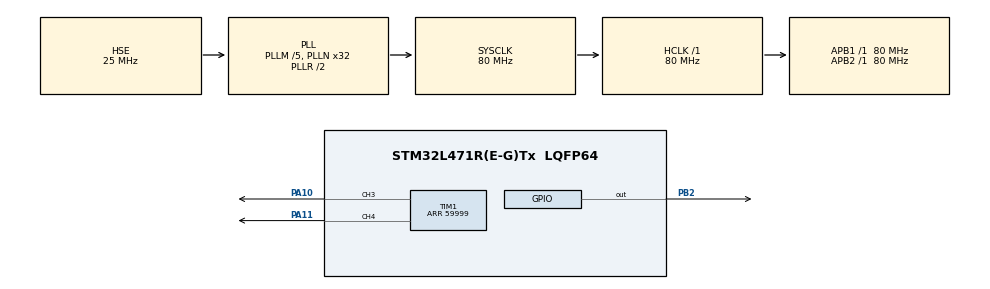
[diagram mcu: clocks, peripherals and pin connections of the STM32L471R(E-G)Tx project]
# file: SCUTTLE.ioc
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Mcu.Family=STM32L4
Mcu.Name=STM32L471R(E-G)Tx
Mcu.Package=LQFP64
NVIC.PriorityGroup=NVIC_PRIORITYGROUP_4
PA10.Signal=S_TIM1_CH3
PA11.Signal=S_TIM1_CH4
PA13\ (JTMS-SWDIO).Mode=Serial_Wire
PA13\ (JTMS-SWDIO).Signal=SYS_JTMS-SWDIO
PA14\ (JTCK-SWCLK).Mode=Serial_Wire
PA14\ (JTCK-SWCLK).Signal=SYS_JTCK-SWCLK
PB2.Signal=GPIO_Output
PB3\ (JTDO-TRACESWO).Signal=SYS_JTDO-SWO
PH0-OSC_IN\ (PH0).Mode=HSE-External-Oscillator
PH0-OSC_IN\ (PH0).Signal=RCC_OSC_IN
PH1-OSC_OUT\ (PH1).Mode=HSE-External-Oscillator
PH1-OSC_OUT\ (PH1).Signal=RCC_OSC_OUT
ProjectManager.HeapSize=0x200
ProjectManager.StackSize=0x400
ProjectManager.TargetToolchain=STM32CubeIDE
RCC.ADCFreq_Value=20000000
RCC.AHBFreq_Value=80000000
RCC.APB1Freq_Value=80000000
RCC.APB1TimFreq_Value=80000000
RCC.APB2Freq_Value=80000000
RCC.APB2TimFreq_Value=80000000
RCC.CortexFreq_Value=80000000
RCC.HCLKFreq_Value=80000000
RCC.HSE_VALUE=25000000
RCC.HSI_VALUE=16000000
RCC.LSE_VALUE=32768
RCC.MSI_VALUE=4000000
RCC.PLLM=5
RCC.PLLN=32
RCC.PLLSourceVirtual=RCC_PLLSOURCE_HSE
RCC.SYSCLKFreq_VALUE=80000000
RCC.SYSCLKSource=RCC_SYSCLKSOURCE_PLLCLK
RCC.VCOOutputFreq_Value=160000000
SH.S_TIM1_CH3.0=TIM1_CH3,PWM Generation3 CH3
SH.S_TIM1_CH4.0=TIM1_CH4,PWM Generation4 CH4
TIM1.Channel-PWM\ Generation3\ CH3=TIM_CHANNEL_3
TIM1.Channel-PWM\ Generation4\ CH4=TIM_CHANNEL_4
TIM1.Period=59999
TIM1.Pulse-PWM\ Generation4\ CH4=29999
board=custom

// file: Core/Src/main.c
/* USER CODE BEGIN Header */
/* USER CODE END Header */
#include "main.h"
#include "motor.h"

TIM_HandleTypeDef htim1;

void SystemClock_Config(void);
static void MX_GPIO_Init(void);
static void MX_TIM1_Init(void);

int main(void)
{

  /* MCU Configuration--------------------------------------------------------*/

  /* Reset of all peripherals, Initializes the Flash interface and the Systick. */
  HAL_Init();

  /* Configure the system clock */
  SystemClock_Config();

  /* Initialize all configured peripherals */
  MX_GPIO_Init();
  MX_TIM1_Init();
  /* USER CODE BEGIN 2 */

  // Start Timer 1 channels 3 and 4
  int32_t duty = -50;
  HAL_GPIO_WritePin(GPIOB, GPIO_PIN_2, GPIO_PIN_SET);
  HAL_TIM_PWM_Start(&htim1, TIM_CHANNEL_3);
  HAL_TIM_PWM_Start(&htim1, TIM_CHANNEL_4);

  // Setup motor2 with TIM1 Channel 3 and 4
  volatile uint32_t *pCCR3 = &(htim1.Instance->CCR3);
  volatile uint32_t *pCCR4 = &(htim1.Instance->CCR4);
  uint32_t Tim2Period = (htim1.Instance->ARR);
  motor_t motor2 = {pCCR3, pCCR4, Tim2Period, duty};

  /* USER CODE END 2 */

  /* Infinite loop */

  /* USER CODE BEGIN WHILE */
  while (1) {
	  HAL_Delay(1000);
	  set_duty(&motor2, duty);
  }
    /* USER CODE END WHILE */

}

void SystemClock_Config(void)
{
  RCC_OscInitTypeDef RCC_OscInitStruct = {0};
  RCC_ClkInitTypeDef RCC_ClkInitStruct = {0};

  /** Configure the main internal regulator output voltage
  */
  if (HAL_PWREx_ControlVoltageScaling(PWR_REGULATOR_VOLTAGE_SCALE1) != HAL_OK)
  {
    Error_Handler();
  }

  /** Initializes the RCC Oscillators according to the specified parameters
  * in the RCC_OscInitTypeDef structure.
  */
  RCC_OscInitStruct.OscillatorType = RCC_OSCILLATORTYPE_HSE;
  RCC_OscInitStruct.HSEState = RCC_HSE_ON;
  RCC_OscInitStruct.PLL.PLLState = RCC_PLL_ON;
  RCC_OscInitStruct.PLL.PLLSource = RCC_PLLSOURCE_HSE;
  RCC_OscInitStruct.PLL.PLLM = 5;
  RCC_OscInitStruct.PLL.PLLN = 32;
  RCC_OscInitStruct.PLL.PLLP = RCC_PLLP_DIV7;
  RCC_OscInitStruct.PLL.PLLQ = RCC_PLLQ_DIV2;
  RCC_OscInitStruct.PLL.PLLR = RCC_PLLR_DIV2;
  if (HAL_RCC_OscConfig(&RCC_OscInitStruct) != HAL_OK)
  {
    Error_Handler();
  }

  /** Initializes the CPU, AHB and APB buses clocks
  */
  RCC_ClkInitStruct.ClockType = RCC_CLOCKTYPE_HCLK|RCC_CLOCKTYPE_SYSCLK
                              |RCC_CLOCKTYPE_PCLK1|RCC_CLOCKTYPE_PCLK2;
  RCC_ClkInitStruct.SYSCLKSource = RCC_SYSCLKSOURCE_PLLCLK;
  RCC_ClkInitStruct.AHBCLKDivider = RCC_SYSCLK_DIV1;
  RCC_ClkInitStruct.APB1CLKDivider = RCC_HCLK_DIV1;
  RCC_ClkInitStruct.APB2CLKDivider = RCC_HCLK_DIV1;

  if (HAL_RCC_ClockConfig(&RCC_ClkInitStruct, FLASH_LATENCY_4) != HAL_OK)
  {
    Error_Handler();
  }
}

static void MX_TIM1_Init(void)
{

  TIM_MasterConfigTypeDef sMasterConfig = {0};
  TIM_OC_InitTypeDef sConfigOC = {0};
  TIM_BreakDeadTimeConfigTypeDef sBreakDeadTimeConfig = {0};

  htim1.Instance = TIM1;
  htim1.Init.Prescaler = 0;
  htim1.Init.CounterMode = TIM_COUNTERMODE_UP;
  htim1.Init.Period = 59999;
  htim1.Init.ClockDivision = TIM_CLOCKDIVISION_DIV1;
  htim1.Init.RepetitionCounter = 0;
  htim1.Init.AutoReloadPreload = TIM_AUTORELOAD_PRELOAD_DISABLE;
  if (HAL_TIM_PWM_Init(&htim1) != HAL_OK)
  {
    Error_Handler();
  }
  sMasterConfig.MasterOutputTrigger = TIM_TRGO_RESET;
  sMasterConfig.MasterOutputTrigger2 = TIM_TRGO2_RESET;
  sMasterConfig.MasterSlaveMode = TIM_MASTERSLAVEMODE_DISABLE;
  if (HAL_TIMEx_MasterConfigSynchronization(&htim1, &sMasterConfig) != HAL_OK)
  {
    Error_Handler();
  }
  sConfigOC.OCMode = TIM_OCMODE_PWM1;
  sConfigOC.Pulse = 0;
  sConfigOC.OCPolarity = TIM_OCPOLARITY_HIGH;
  sConfigOC.OCNPolarity = TIM_OCNPOLARITY_HIGH;
  sConfigOC.OCFastMode = TIM_OCFAST_DISABLE;
  sConfigOC.OCIdleState = TIM_OCIDLESTATE_RESET;
  sConfigOC.OCNIdleState = TIM_OCNIDLESTATE_RESET;
  if (HAL_TIM_PWM_ConfigChannel(&htim1, &sConfigOC, TIM_CHANNEL_3) != HAL_OK)
  {
    Error_Handler();
  }
  sConfigOC.Pulse = 29999;
  if (HAL_TIM_PWM_ConfigChannel(&htim1, &sConfigOC, TIM_CHANNEL_4) != HAL_OK)
  {
    Error_Handler();
  }
  sBreakDeadTimeConfig.OffStateRunMode = TIM_OSSR_DISABLE;
  sBreakDeadTimeConfig.OffStateIDLEMode = TIM_OSSI_DISABLE;
  sBreakDeadTimeConfig.LockLevel = TIM_LOCKLEVEL_OFF;
  sBreakDeadTimeConfig.DeadTime = 0;
  sBreakDeadTimeConfig.BreakState = TIM_BREAK_DISABLE;
  sBreakDeadTimeConfig.BreakPolarity = TIM_BREAKPOLARITY_HIGH;
  sBreakDeadTimeConfig.BreakFilter = 0;
  sBreakDeadTimeConfig.Break2State = TIM_BREAK2_DISABLE;
  sBreakDeadTimeConfig.Break2Polarity = TIM_BREAK2POLARITY_HIGH;
  sBreakDeadTimeConfig.Break2Filter = 0;
  sBreakDeadTimeConfig.AutomaticOutput = TIM_AUTOMATICOUTPUT_DISABLE;
  if (HAL_TIMEx_ConfigBreakDeadTime(&htim1, &sBreakDeadTimeConfig) != HAL_OK)
  {
    Error_Handler();
  }
  HAL_TIM_MspPostInit(&htim1);

}

static void MX_GPIO_Init(void)
{
  GPIO_InitTypeDef GPIO_InitStruct = {0};

  /* GPIO Ports Clock Enable */
  __HAL_RCC_GPIOH_CLK_ENABLE();
  __HAL_RCC_GPIOB_CLK_ENABLE();
  __HAL_RCC_GPIOA_CLK_ENABLE();

  /*Configure GPIO pin Output Level */
  HAL_GPIO_WritePin(GPIOB, GPIO_PIN_2, GPIO_PIN_RESET);

  /*Configure GPIO pin : PB2 */
  GPIO_InitStruct.Pin = GPIO_PIN_2;
  GPIO_InitStruct.Mode = GPIO_MODE_OUTPUT_PP;
  GPIO_InitStruct.Pull = GPIO_NOPULL;
  GPIO_InitStruct.Speed = GPIO_SPEED_FREQ_LOW;
  HAL_GPIO_Init(GPIOB, &GPIO_InitStruct);

}

void Error_Handler(void)
{
}
